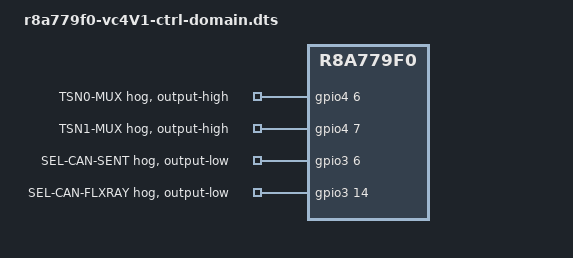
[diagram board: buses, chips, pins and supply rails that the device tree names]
// SPDX-License-Identifier: GPL-2.0
/*
 * Device Tree Source for the VC4 vehicle computer board
 * For V1 schematics, as of 2021-07-13
 *
 * This dts version requires full access for CA55 cores (application domain)
 * to the control domain. Means G4 processor domain needs to grant access
 * before Linux is booted.
 *
 * Copyright (C) 2021-2023 Renesas Electronics Corp.
 */

#include "r8a779f0-vc4V1.dts"
#include "r8a779f0-ctrl-domain.dtsi"

/* SDHI_PWR_SEL is at GPIO4_05 */

&vccq_sdhi {
	status = "okay";
	gpio = <&gpio4 5 GPIO_ACTIVE_HIGH>;
};

&mmc0 {
	vqmcc-supply = <&vccq_sdhi>;
};

/* TSN0_SEL_1_25 is at GPIO4_06 */

&gpio4 {
	tsn0-mux {
		gpio-hog;
		gpios = <6 GPIO_ACTIVE_HIGH>;
		/* For tsn0_phy_2g5 */
		/* output-low; */
		/* For tsn0_phy_1g */
		output-high;
		line-name = "TSN0-MUX";
	};
};

/* TSN1_SEL_1_25 is at GPIO4_07 */

&gpio4 {
	tsn1-mux {
		gpio-hog;
		gpios = <7 GPIO_ACTIVE_HIGH>;
		/* For tsn1_phy_2g5 */
		/* output-low; */
		/* For tsn1_phy_1g */
		output-high;
		line-name = "TSN1-MUX";
	};
};

/* TSN0_WAKE is at GPIO6_22. When using tsn0_phy_2g5, keep high */

&gpio6 {
	/* tsn0-no-wake {
		gpio-hog;
		gpios = <22 GPIO_ACTIVE_HIGH>;
		output-high;
		line-name = "TSN0-NO-WAKE";
	}; */
};

/* TSN1_WAKE is at GPIO6_21. When using tsn1_phy_2g5, keep high */

&gpio6 {
	/* tsn1-no-wake {
		gpio-hog;
		gpios = <21 GPIO_ACTIVE_HIGH>;
		output-high;
		line-name = "TSN1-NO-WAKE";
	}; */
};

/* SEL_CAN_SENT is at GPIO3_06 */

&gpio6 {
	/delete-node/ sel-can-sent;
};

&gpio3 {
	sel-can-sent {
		gpio-hog;
		gpios = <6 GPIO_ACTIVE_HIGH>;
		output-low;
		line-name = "SEL-CAN-SENT";
	};
};

/* SEL_CAN_FLXRAY is at GPIO3_14 */

&gpio6 {
	/delete-node/ sel-can-flxray;
};

&gpio3 {
	sel-can-flxray {
		gpio-hog;
		gpios = <14 GPIO_ACTIVE_HIGH>;
		output-low;
		line-name = "SEL-CAN-FLXRAY";
	};
};
